AUTOSAR XML (schema 314)
package /ComponentType
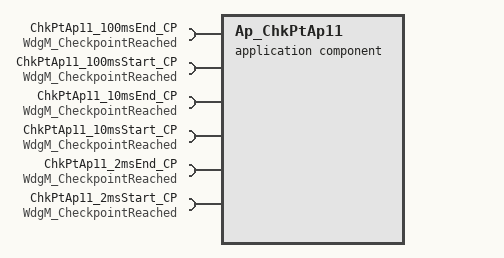
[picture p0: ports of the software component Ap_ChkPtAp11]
  application software component type Ap_ChkPtAp11
    6 x require port, all with client-com-spec=CheckpointReached, required-interface=WdgM_CheckpointReached:
      ChkPtAp11_100msEnd_CP
      ChkPtAp11_100msStart_CP
      ChkPtAp11_10msEnd_CP
      ChkPtAp11_10msStart_CP
      ChkPtAp11_2msEnd_CP
      ChkPtAp11_2msStart_CP
  internal behavior Ap_ChkPtAp11_InternalBehavior: component=Ap_ChkPtAp11
    6 x timing event:
      TMT_ChkPtAp11_100msEnd_Per: start-on-event=ChkPtAp11_100msEnd_Per, period=0.1
      TMT_ChkPtAp11_100msStart_Per: start-on-event=ChkPtAp11_100msStart_Per, period=0.1
      TMT_ChkPtAp11_10msEnd_Per: start-on-event=ChkPtAp11_10msEnd_Per, period=0.01
      TMT_ChkPtAp11_10msStart_Per: start-on-event=ChkPtAp11_10msStart_Per, period=0.01
      TMT_ChkPtAp11_2msEnd_Per: start-on-event=ChkPtAp11_2msEnd_Per, period=0.002
      TMT_ChkPtAp11_2msStart_Per: start-on-event=ChkPtAp11_2msStart_Per, period=0.002
    port-api-options:
      enable-take-address=false, indirect-api=false, port=ChkPtAp11_100msEnd_CP
      enable-take-address=false, indirect-api=false, port=ChkPtAp11_100msStart_CP
      enable-take-address=false, indirect-api=false, port=ChkPtAp11_10msEnd_CP
      enable-take-address=false, indirect-api=false, port=ChkPtAp11_10msStart_CP
      enable-take-address=false, indirect-api=false, port=ChkPtAp11_2msEnd_CP
      enable-take-address=false, indirect-api=false, port=ChkPtAp11_2msStart_CP
    6 x runnable:
      ChkPtAp11_100msEnd_Per
        sync call SC_ChkPtAp11_100msEnd_CP_CheckpointReached: operation=ChkPtAp11_100msEnd_CP.CheckpointReached, timeout=0
      ChkPtAp11_100msStart_Per
        sync call SC_ChkPtAp11_100msStart_CP_CheckpointReached: operation=ChkPtAp11_100msStart_CP.CheckpointReached, timeout=0
      ChkPtAp11_10msEnd_Per
        sync call SC_ChkPtAp11_10msEnd_CP_CheckpointReached: operation=ChkPtAp11_10msEnd_CP.CheckpointReached, timeout=0
      ChkPtAp11_10msStart_Per
        sync call SC_ChkPtAp11_10msStart_CP_CheckpointReached: operation=ChkPtAp11_10msStart_CP.CheckpointReached, timeout=0
      ChkPtAp11_2msEnd_Per
        sync call SC_ChkPtAp11_2msEnd_CP_CheckpointReached: operation=ChkPtAp11_2msEnd_CP.CheckpointReached, timeout=0
      ChkPtAp11_2msStart_Per
        sync call SC_ChkPtAp11_2msStart_CP_CheckpointReached: operation=ChkPtAp11_2msStart_CP.CheckpointReached, timeout=0
  swc implementation Ap_ChkPtAp11_Implementation: behavior=Ap_ChkPtAp11_InternalBehavior
    code-descriptors:
      code Code: type=SRC
